VERSION "K24_CVT"

NS_ :

BS_:

BU_: METER PCM UNKNOWN VSA

BO_ 316 PCM_0x13C: 8 PCM
 SG_ TORQUE_ESTIMATE : 7|16@0- (1,0) [-32768|32767] "raw"  UNKNOWN
 SG_ TORQUE_TARGET : 23|16@0- (1,0) [-32768|32767] "raw"  UNKNOWN
 SG_ APP_SENSOR : 32|8@1+ (0.39215686274509803,0) [0|100] "%"  UNKNOWN
 SG_ TORQUE_STATE : 40|2@1+ (1,0) [0|3] ""  UNKNOWN
 SG_ RSVD_1 : 42|2@1+ (1,0) [0|3] ""  UNKNOWN
 SG_ RSVD_2 : 44|1@1+ (1,0) [0|1] ""  UNKNOWN
 SG_ FRAME_1AA_WINDOW_LATCH : 45|1@1+ (1,0) [0|1] ""  UNKNOWN
 SG_ START_PHASE_LATCH : 46|1@1+ (1,0) [0|1] ""  UNKNOWN
 SG_ DTC_STATUS_7_LATCH : 47|1@1+ (1,0) [0|1] ""  UNKNOWN
 SG_ STOP_CONTACT_GUARD_RAW : 48|1@1+ (1,0) [0|1] ""  UNKNOWN
 SG_ RSVD_3 : 49|1@1+ (1,0) [0|1] ""  UNKNOWN
 SG_ CLUTCH_PEDAL_POSITION_SWITCH_B_STATUS : 50|1@1+ (1,0) [0|1] ""  UNKNOWN
 SG_ RSVD_4 : 51|5@1+ (1,0) [0|31] ""  UNKNOWN
 SG_ CHECKSUM : 56|4@1+ (1,0) [0|15] ""  UNKNOWN
 SG_ COUNTER : 60|2@1+ (1,0) [0|3] ""  UNKNOWN
 SG_ INITIALIZED_STATUS_RAW : 62|1@1+ (1,0) [0|1] ""  UNKNOWN
 SG_ FRAME_1AA_INVALID_OR_FALLBACK_STATE_TBD : 63|1@1+ (1,0) [0|1] ""  UNKNOWN
VAL_ 316 CLUTCH_PEDAL_POSITION_SWITCH_B_STATUS 0 "OPEN" 1 "CLOSE" ;
VAL_ 316 TORQUE_STATE 0 "NORMAL" 1 "VSA_CONTROL_CANDIDATE" 2 "FUEL_CUT" 3 "UNKNOWN" ;

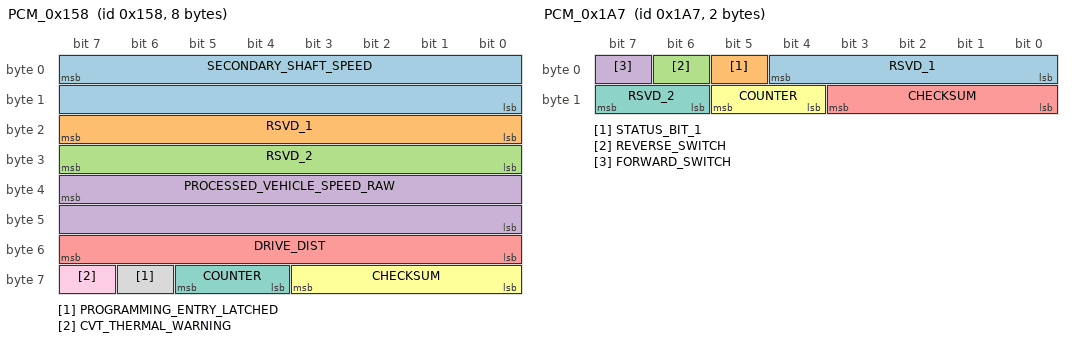
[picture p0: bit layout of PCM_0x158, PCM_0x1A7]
BO_ 344 PCM_0x158: 8 PCM
 SG_ SECONDARY_SHAFT_SPEED : 7|16@0+ (0.01,0) [0|655.35] "km/h"  UNKNOWN
 SG_ RSVD_1 : 16|8@1+ (1,0) [0|255] ""  UNKNOWN
 SG_ RSVD_2 : 24|8@1+ (1,0) [0|255] ""  UNKNOWN
 SG_ PROCESSED_VEHICLE_SPEED_RAW : 39|16@0+ (0.01,0) [0|655.35] "km/h"  UNKNOWN
 SG_ DRIVE_DIST : 48|8@1+ (10,0) [0|2550] "m"  UNKNOWN
 SG_ CHECKSUM : 56|4@1+ (1,0) [0|15] ""  UNKNOWN
 SG_ COUNTER : 60|2@1+ (1,0) [0|3] ""  UNKNOWN
 SG_ PROGRAMMING_ENTRY_LATCHED : 62|1@1+ (1,0) [0|1] ""  UNKNOWN
 SG_ CVT_THERMAL_WARNING : 63|1@1+ (1,0) [0|1] ""  UNKNOWN

BO_ 380 PCM_0x17C: 8 PCM
 SG_ APP_SENSOR : 0|8@1+ (0.39215686274509803,0) [0|100] "%"  UNKNOWN
 SG_ THROTTLE_ABOVE_IDLE_CODE : 8|8@1+ (0.4,0) [0|102] "deg"  UNKNOWN
 SG_ ENGINE_SPEED : 23|16@0+ (1,0) [0|65535] "rpm"  UNKNOWN
 SG_ BRAKE_SWITCH : 32|1@1+ (1,0) [0|1] ""  UNKNOWN
 SG_ CRUISE_CANCEL_EVENT : 33|1@1+ (1,0) [0|1] ""  UNKNOWN
 SG_ CRUISE_FAULT_SPEED_INHIBIT : 34|1@1+ (1,0) [0|1] ""  UNKNOWN
 SG_ CRUISE_ENGAGED : 35|1@1+ (1,0) [0|1] ""  UNKNOWN
 SG_ MIL : 36|1@1+ (1,0) [0|1] ""  UNKNOWN
 SG_ MIL_STATUS : 37|1@1+ (1,0) [0|1] ""  UNKNOWN
 SG_ CRUISE_INDICATOR : 38|1@1+ (1,0) [0|1] ""  UNKNOWN
 SG_ GAS_PEDAL_PRESSED : 39|1@1+ (1,0) [0|1] ""  UNKNOWN
 SG_ RSVD_1 : 40|1@1+ (1,0) [0|1] ""  UNKNOWN
 SG_ APPLICATION_STATUS_ASSERTED : 41|1@1+ (1,0) [0|1] ""  UNKNOWN
 SG_ ACCEL_PEDAL_FAULT : 42|1@1+ (1,0) [0|1] ""  UNKNOWN
 SG_ RSVD_2 : 43|2@1+ (1,0) [0|3] ""  UNKNOWN
 SG_ IDLE_STOP_PRIMARY_CONTROL : 45|1@1+ (1,0) [0|1] ""  UNKNOWN
 SG_ DC_DC_CONVERTER_INFORMATION_CST_OUTPUT : 46|1@1+ (1,0) [0|1] ""  UNKNOWN
 SG_ ENGINE_IDLE_STOP_MODE_CONTROL : 47|1@1+ (1,0) [0|1] ""  UNKNOWN
 SG_ RSVD_3 : 48|5@1+ (1,0) [0|31] ""  UNKNOWN
 SG_ CRUISE_BRAKE_SW_IDLE_STOP_SW : 53|1@1+ (1,0) [0|1] ""  UNKNOWN
 SG_ CRUISE_TRANS_REQUEST_WIRE : 54|2@1+ (1,0) [0|3] ""  UNKNOWN
 SG_ CHECKSUM : 56|4@1+ (1,0) [0|15] ""  UNKNOWN
 SG_ COUNTER : 60|2@1+ (1,0) [0|3] ""  UNKNOWN
 SG_ RSVD_4 : 62|1@1+ (1,0) [0|1] ""  UNKNOWN
 SG_ FIWARN : 63|1@1+ (1,0) [0|1] ""  UNKNOWN
VAL_ 380 CRUISE_BRAKE_SW_IDLE_STOP_SW 0 "CLOSE" 1 "OPEN" ;
VAL_ 380 ENGINE_IDLE_STOP_MODE_CONTROL 0 "UNCONTROLLED" 1 "CONTROLLED" ;
VAL_ 380 CRUISE_INDICATOR 0 "OFF" 1 "ON" ;
VAL_ 380 MIL_STATUS 0 "OFF" 1 "ON" ;
VAL_ 380 MIL 0 "OFF" 1 "ON" ;
VAL_ 380 BRAKE_SWITCH 0 "OFF" 1 "ON" ;

BO_ 401 PCM_0x191: 8 PCM
 SG_ A_T_P_SWITCH : 0|1@1+ (1,0) [0|1] ""  METER,VSA
 SG_ A_T_R_SWITCH : 1|1@1+ (1,0) [0|1] ""  METER,VSA
 SG_ A_T_N_SWITCH : 2|1@1+ (1,0) [0|1] ""  METER,VSA
 SG_ A_T_D_SWITCH : 3|1@1+ (1,0) [0|1] ""  METER,VSA
 SG_ A_T_S_SWITCH : 4|1@1+ (1,0) [0|1] ""  METER,VSA
 SG_ A_T_L_SWITCH : 5|1@1+ (1,0) [0|1] ""  METER,VSA
 SG_ RSVD_1 : 6|1@1+ (1,0) [0|1] ""  METER,VSA
 SG_ TRANSMISSION_FAULT : 7|1@1+ (1,0) [0|1] ""  METER,VSA
 SG_ RSVD_2 : 8|4@1+ (1,0) [0|15] ""  METER,VSA
 SG_ LED_C : 12|1@1+ (1,0) [0|1] ""  METER,VSA
 SG_ LED_B : 13|1@1+ (1,0) [0|1] ""  METER,VSA
 SG_ LED_A : 14|1@1+ (1,0) [0|1] ""  METER,VSA
 SG_ RSVD_3 : 15|1@1+ (1,0) [0|1] ""  METER,VSA
 SG_ RSVD_4 : 16|1@1+ (1,0) [0|1] ""  METER,VSA
 SG_ ECON_MODE_INDICATOR : 17|1@1+ (1,0) [0|1] ""  METER,VSA
 SG_ RSVD_5 : 18|1@1+ (1,0) [0|1] ""  METER,VSA
 SG_ MANUAL_MODE_INDICATOR : 19|1@1+ (1,0) [0|1] ""  METER,VSA
 SG_ CVT_CRITICAL_FAULT : 20|1@1+ (1,0) [0|1] ""  METER,VSA
 SG_ RSVD_6 : 21|1@1+ (1,0) [0|1] ""  METER,VSA
 SG_ COMMUNICATION_SPEED_FAULT : 22|1@1+ (1,0) [0|1] ""  METER,VSA
 SG_ RANGE_DISPLAY_CONTROL : 23|1@1+ (1,0) [0|1] ""  METER,VSA
 SG_ PULLEY_RATIO : 24|8@1+ (0.015625,0) [0|3.984375] "ratio"  METER,VSA
 SG_ CVT_RATIO_TARGET : 32|8@1+ (0.015625,0) [0|3.984375] "ratio"  METER,VSA
 SG_ RANGE_DISPLAY : 40|4@1+ (1,0) [0|15] ""  METER,VSA
 SG_ RSVD_7 : 44|2@1+ (1,0) [0|3] ""  METER,VSA
 SG_ CVT_FLUID_SERVICE_RESET : 46|1@1+ (1,0) [0|1] ""  METER,VSA
 SG_ CVT_FLUID_SERVICE_DUE : 47|1@1+ (1,0) [0|1] ""  METER,VSA
 SG_ CVT_CONTROL_SCHEDULE_CODE : 48|8@1+ (1,0) [0|255] ""  METER,VSA
 SG_ CHECKSUM : 56|4@1+ (1,0) [0|15] ""  METER,VSA
 SG_ COUNTER : 60|2@1+ (1,0) [0|3] ""  METER,VSA
 SG_ CVT_RATIO_RANGE_QUALIFIED : 62|1@1+ (1,0) [0|1] ""  METER,VSA
 SG_ CVT_AUTO_STOP_HOLD : 63|1@1+ (1,0) [0|1] ""  METER,VSA
VAL_ 401 CVT_CONTROL_SCHEDULE_CODE 17 "MANUAL_16_GEAR_STEP_1_7" 18 "MANUAL_16_GEAR_STEP_1_7" 19 "MANUAL_16_GEAR_STEP_1_7" 20 "MANUAL_16_GEAR_STEP_1_7" 21 "MANUAL_16_GEAR_STEP_1_7" 22 "MANUAL_16_GEAR_STEP_1_7" 23 "MANUAL_16_GEAR_STEP_1_7" 33 "ALT_MANUAL_32_GEAR_STEP_1_7" 34 "ALT_MANUAL_32_GEAR_STEP_1_7" 35 "ALT_MANUAL_32_GEAR_STEP_1_7" 36 "ALT_MANUAL_32_GEAR_STEP_1_7" 37 "ALT_MANUAL_32_GEAR_STEP_1_7" 38 "ALT_MANUAL_32_GEAR_STEP_1_7" 39 "ALT_MANUAL_32_GEAR_STEP_1_7" 81 "OVERRIDE_BRANCH" 90 "OVERRIDE_BRANCH" 127 "FAULT_LATCH_OVERRIDE" ;
VAL_ 401 RANGE_DISPLAY 0 "BLANK" 1 "P" 2 "R" 3 "N" 4 "D" 6 "UNRESOLVED" 7 "L" 8 "UNRESOLVED" 10 "S_0X0A" 15 "ALL_SEGMENTS" ;
VAL_ 401 MANUAL_MODE_INDICATOR 0 "OFF" 1 "ON" ;
VAL_ 401 ECON_MODE_INDICATOR 0 "OFF" 1 "ON" ;
VAL_ 401 LED_A 0 "OFF" 1 "ON" ;
VAL_ 401 LED_B 0 "OFF" 1 "ON" ;
VAL_ 401 LED_C 0 "OFF" 1 "ON" ;
VAL_ 401 A_T_L_SWITCH 0 "OFF" 1 "ON" ;
VAL_ 401 A_T_S_SWITCH 0 "OFF" 1 "ON" ;
VAL_ 401 A_T_D_SWITCH 0 "OFF" 1 "ON" ;
VAL_ 401 A_T_N_SWITCH 0 "OFF" 1 "ON" ;
VAL_ 401 A_T_R_SWITCH 0 "OFF" 1 "ON" ;
VAL_ 401 A_T_P_SWITCH 0 "OFF" 1 "ON" ;

BO_ 423 PCM_0x1A7: 2 PCM
 SG_ RSVD_1 : 0|5@1+ (1,0) [0|31] ""  UNKNOWN
 SG_ STATUS_BIT_1 : 5|1@1+ (1,0) [0|1] ""  UNKNOWN
 SG_ REVERSE_SWITCH : 6|1@1+ (1,0) [0|1] ""  UNKNOWN
 SG_ FORWARD_SWITCH : 7|1@1+ (1,0) [0|1] ""  UNKNOWN
 SG_ CHECKSUM : 8|4@1+ (1,0) [0|15] ""  UNKNOWN
 SG_ COUNTER : 12|2@1+ (1,0) [0|3] ""  UNKNOWN
 SG_ RSVD_2 : 14|2@1+ (1,0) [0|3] ""  UNKNOWN

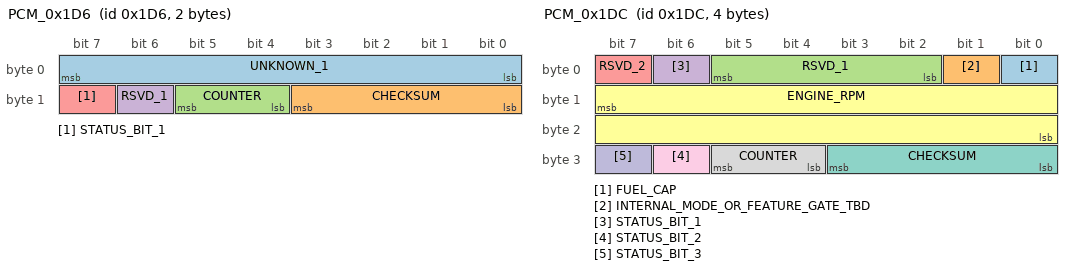
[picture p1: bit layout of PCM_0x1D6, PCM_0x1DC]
BO_ 470 PCM_0x1D6: 2 PCM
 SG_ UNKNOWN_1 : 0|8@1+ (1,0) [0|255] ""  UNKNOWN
 SG_ CHECKSUM : 8|4@1+ (1,0) [0|15] ""  UNKNOWN
 SG_ COUNTER : 12|2@1+ (1,0) [0|3] ""  UNKNOWN
 SG_ RSVD_1 : 14|1@1+ (1,0) [0|1] ""  UNKNOWN
 SG_ STATUS_BIT_1 : 15|1@1+ (1,0) [0|1] ""  UNKNOWN

BO_ 476 PCM_0x1DC: 4 PCM
 SG_ FUEL_CAP : 0|1@1+ (1,0) [0|1] ""  UNKNOWN
 SG_ INTERNAL_MODE_OR_FEATURE_GATE_TBD : 1|1@1+ (1,0) [0|1] ""  UNKNOWN
 SG_ RSVD_1 : 2|4@1+ (1,0) [0|15] ""  UNKNOWN
 SG_ STATUS_BIT_1 : 6|1@1+ (1,0) [0|1] ""  UNKNOWN
 SG_ RSVD_2 : 7|1@1+ (1,0) [0|1] ""  UNKNOWN
 SG_ ENGINE_RPM : 15|16@0+ (1,0) [0|65535] "rpm"  UNKNOWN
 SG_ CHECKSUM : 24|4@1+ (1,0) [0|15] ""  UNKNOWN
 SG_ COUNTER : 28|2@1+ (1,0) [0|3] ""  UNKNOWN
 SG_ STATUS_BIT_2 : 30|1@1+ (1,0) [0|1] ""  UNKNOWN
 SG_ STATUS_BIT_3 : 31|1@1+ (1,0) [0|1] ""  UNKNOWN
VAL_ 476 FUEL_CAP 0 "CLOSE" 1 "OPEN" ;

BO_ 800 BCM_0x320: 8 PCM
 SG_ RSVD_1 : 0|6@1+ (1,0) [0|63] ""  UNKNOWN
 SG_ ENGINE_STATE_CODE_TBD : 6|2@1+ (1,0) [0|3] ""  UNKNOWN
 SG_ STATUS_BIT_1 : 8|1@1+ (1,0) [0|1] ""  UNKNOWN
 SG_ STATUS_BIT_2 : 9|1@1+ (1,0) [0|1] ""  UNKNOWN
 SG_ RSVD_2 : 10|4@1+ (1,0) [0|15] ""  UNKNOWN
 SG_ I_VTEC_INDICATOR_COMMAND : 14|1@1+ (1,0) [0|1] ""  UNKNOWN
 SG_ RSVD_3 : 15|1@1+ (1,0) [0|1] ""  UNKNOWN
 SG_ UNKNOWN_1 : 16|3@1+ (1,0) [0|7] ""  UNKNOWN
 SG_ SIGNED_CAP_OUT_OF_DOMAIN_HIGH_BITS_B2_TBD : 19|3@1+ (1,0) [0|7] ""  UNKNOWN
 SG_ STATUS_BIT_3 : 22|1@1+ (1,0) [0|1] ""  UNKNOWN
 SG_ SIGNED_CAP_OUT_OF_DOMAIN_SIGN_BIT_B2_TBD : 23|1@1+ (1,0) [0|1] ""  UNKNOWN
 SG_ RSVD_4 : 24|8@1+ (1,0) [0|255] ""  UNKNOWN
 SG_ RSVD_5 : 32|7@1+ (1,0) [0|127] ""  UNKNOWN
 SG_ STATUS_BIT_4 : 39|1@1+ (1,0) [0|1] ""  UNKNOWN
 SG_ UNKNOWN_2 : 40|3@1+ (1,0) [0|7] ""  UNKNOWN
 SG_ UNKNOWN_3 : 43|3@1+ (1,0) [0|7] ""  UNKNOWN
 SG_ SIGNED_CAP_OUT_OF_DOMAIN_HIGH_BITS_B5_TBD : 46|2@1+ (1,0) [0|3] ""  UNKNOWN
 SG_ STATUS_BIT_5 : 48|1@1+ (1,0) [0|1] ""  UNKNOWN
 SG_ RSVD_6 : 49|2@1+ (1,0) [0|3] ""  UNKNOWN
 SG_ STATUS_BIT_6 : 51|1@1+ (1,0) [0|1] ""  UNKNOWN
 SG_ RSVD_7 : 52|4@1+ (1,0) [0|15] ""  UNKNOWN
 SG_ CHECKSUM : 56|4@1+ (1,0) [0|15] ""  UNKNOWN
 SG_ COUNTER : 60|2@1+ (1,0) [0|3] ""  UNKNOWN
 SG_ STATUS_BIT_7 : 62|1@1+ (1,0) [0|1] ""  UNKNOWN
 SG_ STATUS_BIT_8 : 63|1@1+ (1,0) [0|1] ""  UNKNOWN
VAL_ 800 I_VTEC_INDICATOR_COMMAND 0 "OFF" 1 "ON" ;

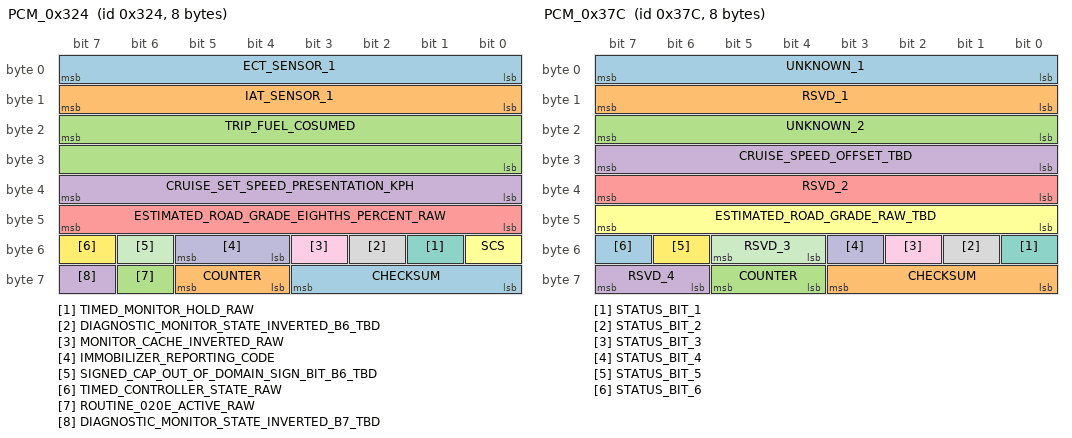
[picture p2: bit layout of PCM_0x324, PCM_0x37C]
BO_ 804 PCM_0x324: 8 PCM
 SG_ ECT_SENSOR_1 : 0|8@1+ (1,-40) [-40|215] "degC"  UNKNOWN
 SG_ IAT_SENSOR_1 : 8|8@1+ (1,-40) [-40|215] "degC"  UNKNOWN
 SG_ TRIP_FUEL_COSUMED : 23|16@0+ (1,0) [0|65535] ""  UNKNOWN
 SG_ CRUISE_SET_SPEED_PRESENTATION_KPH : 32|8@1+ (1,0) [0|255] "km/h"  UNKNOWN
 SG_ ESTIMATED_ROAD_GRADE_EIGHTHS_PERCENT_RAW : 40|8@1- (0.125,0) [-16|15.875] "%"  UNKNOWN
 SG_ SCS : 48|1@1+ (1,0) [0|1] ""  UNKNOWN
 SG_ TIMED_MONITOR_HOLD_RAW : 49|1@1+ (1,0) [0|1] ""  UNKNOWN
 SG_ DIAGNOSTIC_MONITOR_STATE_INVERTED_B6_TBD : 50|1@1+ (1,0) [0|1] ""  UNKNOWN
 SG_ MONITOR_CACHE_INVERTED_RAW : 51|1@1+ (1,0) [0|1] ""  UNKNOWN
 SG_ IMMOBILIZER_REPORTING_CODE : 52|2@1+ (1,0) [0|3] ""  UNKNOWN
 SG_ SIGNED_CAP_OUT_OF_DOMAIN_SIGN_BIT_B6_TBD : 54|1@1+ (1,0) [0|1] ""  UNKNOWN
 SG_ TIMED_CONTROLLER_STATE_RAW : 55|1@1+ (1,0) [0|1] ""  UNKNOWN
 SG_ CHECKSUM : 56|4@1+ (1,0) [0|15] ""  UNKNOWN
 SG_ COUNTER : 60|2@1+ (1,0) [0|3] ""  UNKNOWN
 SG_ ROUTINE_020E_ACTIVE_RAW : 62|1@1+ (1,0) [0|1] ""  UNKNOWN
 SG_ DIAGNOSTIC_MONITOR_STATE_INVERTED_B7_TBD : 63|1@1+ (1,0) [0|1] ""  UNKNOWN
VAL_ 804 IMMOBILIZER_REPORTING_CODE 0 "COMPLETE_ACCEPTED" 1 "INCOMPLETE" 2 "COMPLETE_NOT_ACCEPTED" ;
VAL_ 804 SCS 0 "OPEN" 1 "SHORT" ;
VAL_ 804 IAT_SENSOR_1 255 "INVALID" ;
VAL_ 804 ECT_SENSOR_1 255 "INVALID" ;

BO_ 808 XXX_0x328: 8 PCM
 SG_ RSVD_1 : 0|8@1+ (1,0) [0|255] ""  UNKNOWN
 SG_ IDLE_STOP_CVT_PREREQUISITE_RAW : 8|8@1+ (1,0) [0|255] ""  UNKNOWN
 SG_ RSVD_2 : 16|8@1+ (1,0) [0|255] ""  UNKNOWN
 SG_ RSVD_3 : 24|2@1+ (1,0) [0|3] ""  UNKNOWN
 SG_ STOCK_DISABLED_IDLE_STOP_PREREQUISITE_RAW : 26|1@1+ (1,0) [0|1] ""  UNKNOWN
 SG_ RSVD_4 : 27|5@1+ (1,0) [0|31] ""  UNKNOWN
 SG_ RSVD_5 : 32|8@1+ (1,0) [0|255] ""  UNKNOWN
 SG_ RSVD_6 : 40|2@1+ (1,0) [0|3] ""  UNKNOWN
 SG_ THROTTLE_ACTUATOR_SUPPLY_VOLTAGE_OFF_EVENT_TBD : 42|1@1+ (1,0) [0|1] ""  UNKNOWN
 SG_ STATUS_BIT_1 : 43|1@1+ (1,0) [0|1] ""  UNKNOWN
 SG_ SECONDARY_REQUEST_LIMIT_ENABLE_RAW : 44|1@1+ (1,0) [0|1] ""  UNKNOWN
 SG_ RSVD_7 : 45|1@1+ (1,0) [0|1] ""  UNKNOWN
 SG_ DISCRETE_INPUT_QUALIFICATION_RAW : 46|1@1+ (1,0) [0|1] ""  UNKNOWN
 SG_ STARTUP_QUALIFICATION_COMPLETE_RAW : 47|1@1+ (1,0) [0|1] ""  UNKNOWN
 SG_ CRUISE_TRANSITION_REASON_CODE_RAW : 48|4@1+ (1,0) [0|15] ""  UNKNOWN
 SG_ RSVD_8 : 52|2@1+ (1,0) [0|3] ""  UNKNOWN
 SG_ STATUS_BIT_2 : 54|1@1+ (1,0) [0|1] ""  UNKNOWN
 SG_ RSVD_9 : 55|1@1+ (1,0) [0|1] ""  UNKNOWN
 SG_ CHECKSUM : 56|4@1+ (1,0) [0|15] ""  UNKNOWN
 SG_ COUNTER : 60|2@1+ (1,0) [0|3] ""  UNKNOWN
 SG_ THREE_BYTE_BITWISE_INTERSECTION_NONZERO_TBD : 62|1@1+ (1,0) [0|1] ""  UNKNOWN
 SG_ ACCELERATOR_PEDAL_DUAL_TRACK_FAULT_ANY : 63|1@1+ (1,0) [0|1] ""  UNKNOWN

BO_ 892 PCM_0x37C: 8 PCM
 SG_ UNKNOWN_1 : 0|8@1+ (1,0) [0|255] ""  UNKNOWN
 SG_ RSVD_1 : 8|8@1+ (1,0) [0|255] ""  UNKNOWN
 SG_ UNKNOWN_2 : 16|8@1+ (1,0) [0|255] ""  UNKNOWN
 SG_ CRUISE_SPEED_OFFSET_TBD : 24|8@1- (0.1,0) [-12.8|12.700000000000001] "km/h"  UNKNOWN
 SG_ RSVD_2 : 32|8@1+ (1,0) [0|255] ""  UNKNOWN
 SG_ ESTIMATED_ROAD_GRADE_RAW_TBD : 40|8@1+ (1,0) [0|255] ""  UNKNOWN
 SG_ STATUS_BIT_1 : 48|1@1+ (1,0) [0|1] ""  UNKNOWN
 SG_ STATUS_BIT_2 : 49|1@1+ (1,0) [0|1] ""  UNKNOWN
 SG_ STATUS_BIT_3 : 50|1@1+ (1,0) [0|1] ""  UNKNOWN
 SG_ STATUS_BIT_4 : 51|1@1+ (1,0) [0|1] ""  UNKNOWN
 SG_ RSVD_3 : 52|2@1+ (1,0) [0|3] ""  UNKNOWN
 SG_ STATUS_BIT_5 : 54|1@1+ (1,0) [0|1] ""  UNKNOWN
 SG_ STATUS_BIT_6 : 55|1@1+ (1,0) [0|1] ""  UNKNOWN
 SG_ CHECKSUM : 56|4@1+ (1,0) [0|15] ""  UNKNOWN
 SG_ COUNTER : 60|2@1+ (1,0) [0|3] ""  UNKNOWN
 SG_ RSVD_4 : 62|2@1+ (1,0) [0|3] ""  UNKNOWN

BO_ 983 PCM_0x3D7: 8 PCM
 SG_ MULTIPLEX_HEADER : 0|8@1+ (1,0) [0|255] ""  UNKNOWN
 SG_ RETAINED_BANK_A_CODE_WORD_0_PAGE_0 m0 : 15|16@0+ (1,0) [0|65535] ""  UNKNOWN
 SG_ RETAINED_BANK_A_CODE_WORD_0_PAGE_1 m1 : 15|16@0+ (1,0) [0|65535] ""  UNKNOWN
 SG_ RETAINED_BANK_A_CODE_WORD_1_PAGE_0 m0 : 31|16@0+ (1,0) [0|65535] ""  UNKNOWN
 SG_ RETAINED_BANK_A_CODE_WORD_1_PAGE_1 m1 : 31|16@0+ (1,0) [0|65535] ""  UNKNOWN
 SG_ RETAINED_BANK_A_CODE_WORD_2_PAGE_0 m0 : 47|16@0+ (1,0) [0|65535] ""  UNKNOWN
 SG_ RETAINED_BANK_A_CODE_WORD_2_PAGE_1 m1 : 47|16@0+ (1,0) [0|65535] ""  UNKNOWN
 SG_ CHECKSUM : 56|4@1+ (1,0) [0|15] ""  UNKNOWN
 SG_ COUNTER : 60|2@1+ (1,0) [0|3] ""  UNKNOWN
 SG_ PAGE_INDEX M : 62|1@1+ (1,0) [0|1] ""  UNKNOWN
 SG_ PROTOCOL_BIT7 : 63|1@1+ (1,0) [0|1] ""  UNKNOWN
VAL_ 983 PAGE_INDEX 0 "SLOTS0_TO2" 1 "SLOTS3_TO5" ;
SG_MUL_VAL_ 983 RETAINED_BANK_A_CODE_WORD_0_PAGE_0 PAGE_INDEX 0-0;
SG_MUL_VAL_ 983 RETAINED_BANK_A_CODE_WORD_0_PAGE_1 PAGE_INDEX 1-1;
SG_MUL_VAL_ 983 RETAINED_BANK_A_CODE_WORD_1_PAGE_0 PAGE_INDEX 0-0;
SG_MUL_VAL_ 983 RETAINED_BANK_A_CODE_WORD_1_PAGE_1 PAGE_INDEX 1-1;
SG_MUL_VAL_ 983 RETAINED_BANK_A_CODE_WORD_2_PAGE_0 PAGE_INDEX 0-0;
SG_MUL_VAL_ 983 RETAINED_BANK_A_CODE_WORD_2_PAGE_1 PAGE_INDEX 1-1;

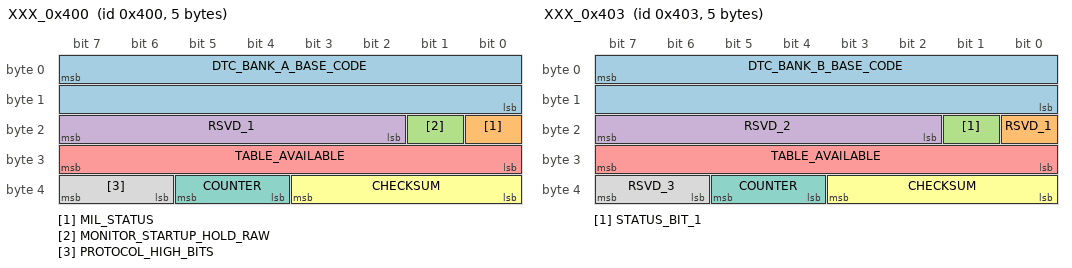
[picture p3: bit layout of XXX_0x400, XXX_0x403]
BO_ 1024 XXX_0x400: 5 PCM
 SG_ DTC_BANK_A_BASE_CODE : 7|16@0+ (1,0) [0|65535] ""  UNKNOWN
 SG_ MIL_STATUS : 16|1@1+ (1,0) [0|1] ""  UNKNOWN
 SG_ MONITOR_STARTUP_HOLD_RAW : 17|1@1+ (1,0) [0|1] ""  UNKNOWN
 SG_ RSVD_1 : 18|6@1+ (1,0) [0|63] ""  UNKNOWN
 SG_ TABLE_AVAILABLE : 24|8@1+ (1,0) [0|255] ""  UNKNOWN
 SG_ CHECKSUM : 32|4@1+ (1,0) [0|15] ""  UNKNOWN
 SG_ COUNTER : 36|2@1+ (1,0) [0|3] ""  UNKNOWN
 SG_ PROTOCOL_HIGH_BITS : 38|2@1+ (1,0) [0|3] ""  UNKNOWN
VAL_ 1024 MIL_STATUS 0 "OFF" 1 "ON" ;

BO_ 1027 XXX_0x403: 5 PCM
 SG_ DTC_BANK_B_BASE_CODE : 7|16@0+ (1,0) [0|65535] ""  UNKNOWN
 SG_ RSVD_1 : 16|1@1+ (1,0) [0|1] ""  UNKNOWN
 SG_ STATUS_BIT_1 : 17|1@1+ (1,0) [0|1] ""  UNKNOWN
 SG_ RSVD_2 : 18|6@1+ (1,0) [0|63] ""  UNKNOWN
 SG_ TABLE_AVAILABLE : 24|8@1+ (1,0) [0|255] ""  UNKNOWN
 SG_ CHECKSUM : 32|4@1+ (1,0) [0|15] ""  UNKNOWN
 SG_ COUNTER : 36|2@1+ (1,0) [0|3] ""  UNKNOWN
 SG_ RSVD_3 : 38|2@1+ (1,0) [0|3] ""  UNKNOWN

BO_ 1036 XXX_0x40C: 8 PCM
 SG_ MULTIPLEX_PAGE M : 0|4@1+ (1,0) [0|15] ""  UNKNOWN
 SG_ MULTIPLEX_GROUP : 4|2@1+ (1,0) [0|3] ""  UNKNOWN
 SG_ DIAGNOSTIC_EVENT_STATE : 6|2@1+ (1,0) [0|3] ""  UNKNOWN
 SG_ RSVD_1 m0 : 8|8@1+ (1,0) [0|255] ""  UNKNOWN
 SG_ P01_VIN_CHARACTERS_1_6_10_B1 m1 : 8|8@1+ (1,0) [0|255] ""  UNKNOWN
 SG_ P02_VIN_CHARACTERS_7_12_11_B1 m2 : 8|8@1+ (1,0) [0|255] ""  UNKNOWN
 SG_ P03_VIN_CHARACTERS_13_17_12_B1 m3 : 8|8@1+ (1,0) [0|255] ""  UNKNOWN
 SG_ P04_ECUID1 m4 : 8|8@1+ (1,0) [0|255] ""  UNKNOWN
 SG_ P05_ENGINE_SPEED m5 : 15|16@0+ (0.25,0) [0|16383.75] "rpm"  UNKNOWN
 SG_ P06_IAT_SENSOR_1_V m6 : 8|8@1+ (0.0196078431372549,0) [0|5] "V"  UNKNOWN
 SG_ P07_VEHICLE_SPEED_PCM m7 : 8|8@1+ (1,0) [0|255] "km/h"  UNKNOWN
 SG_ P08_APP_SENSOR m8 : 15|16@0+ (0.005,0) [0|327.675] "%"  UNKNOWN
 SG_ P09_TARGET_TH_VLV m9 : 15|16@0+ (0.005,0) [0|327.675] "deg"  UNKNOWN
 SG_ RSVD_2 m10 : 8|8@1+ (1,0) [0|255] ""  UNKNOWN
 SG_ P0B_FSS m11 : 8|8@1+ (1,0) [0|255] ""  UNKNOWN
 SG_ RSVD_3 m12 : 8|8@1+ (1,0) [0|255] ""  UNKNOWN
 SG_ RSVD_4 m13 : 8|8@1+ (1,0) [0|255] ""  UNKNOWN
 SG_ P0E_MAF_SENSOR m14 : 15|16@0+ (0.01,0) [0|655.35] "g/s"  UNKNOWN
 SG_ P0F_FUEL_LEVEL m15 : 8|8@1+ (0.39215686274509803,0) [0|100] "%"  UNKNOWN
 SG_ P00_DIAGNOSTICEVENTORFREEZEDTCCODE_5 m0 : 23|16@0+ (1,0) [0|65535] ""  UNKNOWN
 SG_ P01_VIN_CHARACTERS_1_6_10_B2 m1 : 16|8@1+ (1,0) [0|255] ""  UNKNOWN
 SG_ P02_VIN_CHARACTERS_7_12_11_B2 m2 : 16|8@1+ (1,0) [0|255] ""  UNKNOWN
 SG_ P03_VIN_CHARACTERS_13_17_12_B2 m3 : 16|8@1+ (1,0) [0|255] ""  UNKNOWN
 SG_ P04_ECUID2 m4 : 16|8@1+ (1,0) [0|255] ""  UNKNOWN
 SG_ P06_IAT_SENSOR_1_DEG_C m6 : 16|8@1+ (1,-40) [-40|215] "degC"  UNKNOWN
 SG_ P07_CLV m7 : 16|8@1+ (0.39215686274509803,0) [0|100] "%"  UNKNOWN
 SG_ RSVD_5 m10 : 16|8@1+ (1,0) [0|255] ""  UNKNOWN
 SG_ P0B_HO2S_S2 m11 : 16|8@1+ (0.0196078431372549,0) [0|5] "V"  UNKNOWN
 SG_ RSVD_6 m12 : 16|8@1+ (1,0) [0|255] ""  UNKNOWN
 SG_ P0D_AF_SENSOR m13 : 23|16@0+ (1,0) [0|65535] ""  UNKNOWN
 SG_ RSVD_7 m15 : 16|8@1+ (1,0) [0|255] ""  UNKNOWN
 SG_ P01_VIN_CHARACTERS_1_6_10_B3 m1 : 24|8@1+ (1,0) [0|255] ""  UNKNOWN
 SG_ P02_VIN_CHARACTERS_7_12_11_B3 m2 : 24|8@1+ (1,0) [0|255] ""  UNKNOWN
 SG_ P03_VIN_CHARACTERS_13_17_12_B3 m3 : 24|8@1+ (1,0) [0|255] ""  UNKNOWN
 SG_ P04_ECUID3 m4 : 24|8@1+ (1,0) [0|255] ""  UNKNOWN
 SG_ P05_TP_SENSOR m5 : 24|8@1+ (0.39215686274509803,0) [0|100] "%"  UNKNOWN
 SG_ P06_MAP_SENSOR_V m6 : 24|8@1+ (0.0196078431372549,0) [0|5] "V"  UNKNOWN
 SG_ P07_SPARK_ADVANCE m7 : 24|8@1+ (0.5,-64) [-64|63.5] "deg"  UNKNOWN
 SG_ P08_TP_SENSOR_1 m8 : 24|8@1+ (0.0196078431372549,0) [0|5] "V"  UNKNOWN
 SG_ P09_THROTTLE_AN12_BASELINE_RAW m9 : 24|8@1+ (1,0) [0|255] ""  UNKNOWN
 SG_ P0A_AF_LAMBDA m10 : 31|16@0+ (3.0517578125e-05,0) [0|1.999969482421875] "ratio"  UNKNOWN
 SG_ RSVD_8 m11 : 24|8@1+ (1,0) [0|255] ""  UNKNOWN
 SG_ RSVD_9 m12 : 24|8@1+ (1,0) [0|255] ""  UNKNOWN
 SG_ P0E_CMP_CTRL m14 : 24|8@1+ (1,0) [0|255] ""  UNKNOWN
 SG_ RSVD_10 m15 : 24|8@1+ (1,0) [0|255] ""  UNKNOWN
 SG_ P00_FORMATORLENGTHCODE_6 m0 : 32|8@1+ (1,0) [0|255] ""  UNKNOWN
 SG_ P01_VIN_CHARACTERS_1_6_10_B4 m1 : 32|8@1+ (1,0) [0|255] ""  UNKNOWN
 SG_ P02_VIN_CHARACTERS_7_12_11_B4 m2 : 32|8@1+ (1,0) [0|255] ""  UNKNOWN
 SG_ P03_VIN_CHARACTERS_13_17_12_B4 m3 : 32|8@1+ (1,0) [0|255] ""  UNKNOWN
 SG_ P04_ECUID4 m4 : 32|8@1+ (1,0) [0|255] ""  UNKNOWN
 SG_ P05_REL_TP_SENSOR m5 : 32|8@1+ (0.39215686274509803,0) [0|100] "%"  UNKNOWN
 SG_ P06_MAP_SENSOR_K_PA m6 : 32|8@1+ (1,0) [0|255] "kPa"  UNKNOWN
 SG_ P07_CONTROL_MODULE_VOLTAGE_CLAMPED_RAW m7 : 32|8@1+ (1,0) [0|255] "raw"  UNKNOWN
 SG_ P08_TP_SENSOR_2 m8 : 32|8@1+ (0.0196078431372549,0) [0|5] "V"  UNKNOWN
 SG_ P09_THROTTLE_AN45_BASELINE_RAW m9 : 32|8@1+ (1,0) [0|255] ""  UNKNOWN
 SG_ RSVD_11 m11 : 32|8@1+ (1,0) [0|255] ""  UNKNOWN
 SG_ RSVD_12 m12 : 32|8@1+ (1,0) [0|255] ""  UNKNOWN
 SG_ P0D_MAF_SENSOR m13 : 32|8@1+ (0.0196078431372549,0) [0|5] "V"  UNKNOWN
 SG_ P0E_ENGINE_RUNTIME_RAW m14 : 39|16@0+ (1,0) [0|65535] "s"  UNKNOWN
 SG_ RSVD_13 m15 : 32|8@1+ (1,0) [0|255] ""  UNKNOWN
 SG_ RSVD_14 m0 : 40|8@1+ (1,0) [0|255] ""  UNKNOWN
 SG_ P01_VIN_CHARACTERS_1_6_10_B5 m1 : 40|8@1+ (1,0) [0|255] ""  UNKNOWN
 SG_ P02_VIN_CHARACTERS_7_12_11_B5 m2 : 40|8@1+ (1,0) [0|255] ""  UNKNOWN
 SG_ P03_VIN_CHARACTERS_13_17_12_B5 m3 : 40|8@1+ (1,0) [0|255] ""  UNKNOWN
 SG_ P04_ECUID5 m4 : 40|8@1+ (1,0) [0|255] ""  UNKNOWN
 SG_ P05_ECT_SENSOR_1_V m5 : 40|8@1+ (0.0196078431372549,0) [0|5] "V"  UNKNOWN
 SG_ P06_BARO_SENSOR_V m6 : 40|8@1+ (0.0196078431372549,0) [0|5] "V"  UNKNOWN
 SG_ P07_APP_SENSOR_A m7 : 40|8@1+ (0.0196078431372549,0) [0|5] "V"  UNKNOWN
 SG_ P08_THROTTLE_VLV m8 : 47|16@0+ (0.005,0) [0|327.675] "deg"  UNKNOWN
 SG_ P09_IDLE_TARGET_TH m9 : 47|16@0+ (0.005,0) [0|327.675] "deg"  UNKNOWN
 SG_ P0A_AF_FB_ST_FUEL_TRIM m10 : 40|8@1+ (0.0078125,0) [0|1.9921875] "ratio"  UNKNOWN
 SG_ RSVD_15 m11 : 40|8@1+ (1,0) [0|255] ""  UNKNOWN
 SG_ P0C_F_INJECTOR m12 : 47|16@0+ (0.004,0) [0|262.14] "ms"  UNKNOWN
 SG_ P0D_AF_LAMBDA_CMD m13 : 47|16@0+ (3.0517578125e-05,0) [0|1.999969482421875] "ratio"  UNKNOWN
 SG_ RSVD_16 m15 : 40|8@1+ (1,0) [0|255] ""  UNKNOWN
 SG_ RSVD_17 m0 : 48|8@1+ (1,0) [0|255] ""  UNKNOWN
 SG_ P01_VIN_CHARACTERS_1_6_10_B6 m1 : 48|8@1+ (1,0) [0|255] ""  UNKNOWN
 SG_ P02_VIN_CHARACTERS_7_12_11_B6 m2 : 48|8@1+ (1,0) [0|255] ""  UNKNOWN
 SG_ P03_IDENTIFICATIONEXTRABYTE_TBD_13 m3 : 48|8@1+ (1,0) [0|255] ""  UNKNOWN
 SG_ RSVD_18 m4 : 48|8@1+ (1,0) [0|255] ""  UNKNOWN
 SG_ P05_ECT_SENSOR_1_DEG_C m5 : 48|8@1+ (1,-40) [-40|215] "degC"  UNKNOWN
 SG_ P06_BARO_SENSOR_K_PA m6 : 48|8@1+ (1,0) [0|255] "kPa"  UNKNOWN
 SG_ P07_APP_SENSOR_B m7 : 48|8@1+ (0.0196078431372549,0) [0|5] "V"  UNKNOWN
 SG_ P0A_AF_FB_AVE_LT_FUEL_TRIM m10 : 48|8@1+ (0.0078125,0) [0|1.9921875] "ratio"  UNKNOWN
 SG_ RSVD_19 m11 : 48|8@1+ (1,0) [0|255] ""  UNKNOWN
 SG_ P0E_EVAP_PC_DUTY m14 : 48|8@1+ (0.39215686274509803,0) [0|100] "%"  UNKNOWN
 SG_ RSVD_20 m15 : 48|8@1+ (1,0) [0|255] ""  UNKNOWN
 SG_ CHECKSUM : 56|4@1+ (1,0) [0|15] ""  UNKNOWN
 SG_ COUNTER : 60|2@1+ (1,0) [0|3] ""  UNKNOWN
 SG_ DIAGNOSTIC_STATUS_FLAG6 : 62|1@1+ (1,0) [0|1] ""  UNKNOWN
 SG_ DIAGNOSTIC_STATUS_FLAG7 : 63|1@1+ (1,0) [0|1] ""  UNKNOWN
VAL_ 1036 P0B_FSS 0 "NONE" 1 "OL_COND" 2 "CLOSED" 4 "OL_DRV" 8 "OL_DTC" 16 "CL_O2_SX" ;
SG_MUL_VAL_ 1036 RSVD_1 MULTIPLEX_PAGE 0-0;
SG_MUL_VAL_ 1036 P01_VIN_CHARACTERS_1_6_10_B1 MULTIPLEX_PAGE 1-1;
SG_MUL_VAL_ 1036 P02_VIN_CHARACTERS_7_12_11_B1 MULTIPLEX_PAGE 2-2;
SG_MUL_VAL_ 1036 P03_VIN_CHARACTERS_13_17_12_B1 MULTIPLEX_PAGE 3-3;
SG_MUL_VAL_ 1036 P04_ECUID1 MULTIPLEX_PAGE 4-4;
SG_MUL_VAL_ 1036 P05_ENGINE_SPEED MULTIPLEX_PAGE 5-5;
SG_MUL_VAL_ 1036 P06_IAT_SENSOR_1_V MULTIPLEX_PAGE 6-6;
SG_MUL_VAL_ 1036 P07_VEHICLE_SPEED_PCM MULTIPLEX_PAGE 7-7;
SG_MUL_VAL_ 1036 P08_APP_SENSOR MULTIPLEX_PAGE 8-8;
SG_MUL_VAL_ 1036 P09_TARGET_TH_VLV MULTIPLEX_PAGE 9-9;
SG_MUL_VAL_ 1036 RSVD_2 MULTIPLEX_PAGE 10-10;
SG_MUL_VAL_ 1036 P0B_FSS MULTIPLEX_PAGE 11-11;
SG_MUL_VAL_ 1036 RSVD_3 MULTIPLEX_PAGE 12-12;
SG_MUL_VAL_ 1036 RSVD_4 MULTIPLEX_PAGE 13-13;
SG_MUL_VAL_ 1036 P0E_MAF_SENSOR MULTIPLEX_PAGE 14-14;
SG_MUL_VAL_ 1036 P0F_FUEL_LEVEL MULTIPLEX_PAGE 15-15;
SG_MUL_VAL_ 1036 P00_DIAGNOSTICEVENTORFREEZEDTCCODE_5 MULTIPLEX_PAGE 0-0;
SG_MUL_VAL_ 1036 P01_VIN_CHARACTERS_1_6_10_B2 MULTIPLEX_PAGE 1-1;
SG_MUL_VAL_ 1036 P02_VIN_CHARACTERS_7_12_11_B2 MULTIPLEX_PAGE 2-2;
SG_MUL_VAL_ 1036 P03_VIN_CHARACTERS_13_17_12_B2 MULTIPLEX_PAGE 3-3;
SG_MUL_VAL_ 1036 P04_ECUID2 MULTIPLEX_PAGE 4-4;
SG_MUL_VAL_ 1036 P06_IAT_SENSOR_1_DEG_C MULTIPLEX_PAGE 6-6;
SG_MUL_VAL_ 1036 P07_CLV MULTIPLEX_PAGE 7-7;
SG_MUL_VAL_ 1036 RSVD_5 MULTIPLEX_PAGE 10-10;
SG_MUL_VAL_ 1036 P0B_HO2S_S2 MULTIPLEX_PAGE 11-11;
SG_MUL_VAL_ 1036 RSVD_6 MULTIPLEX_PAGE 12-12;
SG_MUL_VAL_ 1036 P0D_AF_SENSOR MULTIPLEX_PAGE 13-13;
SG_MUL_VAL_ 1036 RSVD_7 MULTIPLEX_PAGE 15-15;
SG_MUL_VAL_ 1036 P01_VIN_CHARACTERS_1_6_10_B3 MULTIPLEX_PAGE 1-1;
SG_MUL_VAL_ 1036 P02_VIN_CHARACTERS_7_12_11_B3 MULTIPLEX_PAGE 2-2;
SG_MUL_VAL_ 1036 P03_VIN_CHARACTERS_13_17_12_B3 MULTIPLEX_PAGE 3-3;
SG_MUL_VAL_ 1036 P04_ECUID3 MULTIPLEX_PAGE 4-4;
SG_MUL_VAL_ 1036 P05_TP_SENSOR MULTIPLEX_PAGE 5-5;
SG_MUL_VAL_ 1036 P06_MAP_SENSOR_V MULTIPLEX_PAGE 6-6;
SG_MUL_VAL_ 1036 P07_SPARK_ADVANCE MULTIPLEX_PAGE 7-7;
SG_MUL_VAL_ 1036 P08_TP_SENSOR_1 MULTIPLEX_PAGE 8-8;
SG_MUL_VAL_ 1036 P09_THROTTLE_AN12_BASELINE_RAW MULTIPLEX_PAGE 9-9;
SG_MUL_VAL_ 1036 P0A_AF_LAMBDA MULTIPLEX_PAGE 10-10;
SG_MUL_VAL_ 1036 RSVD_8 MULTIPLEX_PAGE 11-11;
SG_MUL_VAL_ 1036 RSVD_9 MULTIPLEX_PAGE 12-12;
SG_MUL_VAL_ 1036 P0E_CMP_CTRL MULTIPLEX_PAGE 14-14;
SG_MUL_VAL_ 1036 RSVD_10 MULTIPLEX_PAGE 15-15;
SG_MUL_VAL_ 1036 P00_FORMATORLENGTHCODE_6 MULTIPLEX_PAGE 0-0;
SG_MUL_VAL_ 1036 P01_VIN_CHARACTERS_1_6_10_B4 MULTIPLEX_PAGE 1-1;
SG_MUL_VAL_ 1036 P02_VIN_CHARACTERS_7_12_11_B4 MULTIPLEX_PAGE 2-2;
SG_MUL_VAL_ 1036 P03_VIN_CHARACTERS_13_17_12_B4 MULTIPLEX_PAGE 3-3;
SG_MUL_VAL_ 1036 P04_ECUID4 MULTIPLEX_PAGE 4-4;
SG_MUL_VAL_ 1036 P05_REL_TP_SENSOR MULTIPLEX_PAGE 5-5;
SG_MUL_VAL_ 1036 P06_MAP_SENSOR_K_PA MULTIPLEX_PAGE 6-6;
SG_MUL_VAL_ 1036 P07_CONTROL_MODULE_VOLTAGE_CLAMPED_RAW MULTIPLEX_PAGE 7-7;
SG_MUL_VAL_ 1036 P08_TP_SENSOR_2 MULTIPLEX_PAGE 8-8;
SG_MUL_VAL_ 1036 P09_THROTTLE_AN45_BASELINE_RAW MULTIPLEX_PAGE 9-9;
SG_MUL_VAL_ 1036 RSVD_11 MULTIPLEX_PAGE 11-11;
SG_MUL_VAL_ 1036 RSVD_12 MULTIPLEX_PAGE 12-12;
SG_MUL_VAL_ 1036 P0D_MAF_SENSOR MULTIPLEX_PAGE 13-13;
SG_MUL_VAL_ 1036 P0E_ENGINE_RUNTIME_RAW MULTIPLEX_PAGE 14-14;
SG_MUL_VAL_ 1036 RSVD_13 MULTIPLEX_PAGE 15-15;
SG_MUL_VAL_ 1036 RSVD_14 MULTIPLEX_PAGE 0-0;
SG_MUL_VAL_ 1036 P01_VIN_CHARACTERS_1_6_10_B5 MULTIPLEX_PAGE 1-1;
SG_MUL_VAL_ 1036 P02_VIN_CHARACTERS_7_12_11_B5 MULTIPLEX_PAGE 2-2;
SG_MUL_VAL_ 1036 P03_VIN_CHARACTERS_13_17_12_B5 MULTIPLEX_PAGE 3-3;
SG_MUL_VAL_ 1036 P04_ECUID5 MULTIPLEX_PAGE 4-4;
SG_MUL_VAL_ 1036 P05_ECT_SENSOR_1_V MULTIPLEX_PAGE 5-5;
SG_MUL_VAL_ 1036 P06_BARO_SENSOR_V MULTIPLEX_PAGE 6-6;
SG_MUL_VAL_ 1036 P07_APP_SENSOR_A MULTIPLEX_PAGE 7-7;
SG_MUL_VAL_ 1036 P08_THROTTLE_VLV MULTIPLEX_PAGE 8-8;
SG_MUL_VAL_ 1036 P09_IDLE_TARGET_TH MULTIPLEX_PAGE 9-9;
SG_MUL_VAL_ 1036 P0A_AF_FB_ST_FUEL_TRIM MULTIPLEX_PAGE 10-10;
SG_MUL_VAL_ 1036 RSVD_15 MULTIPLEX_PAGE 11-11;
SG_MUL_VAL_ 1036 P0C_F_INJECTOR MULTIPLEX_PAGE 12-12;
SG_MUL_VAL_ 1036 P0D_AF_LAMBDA_CMD MULTIPLEX_PAGE 13-13;
SG_MUL_VAL_ 1036 RSVD_16 MULTIPLEX_PAGE 15-15;
SG_MUL_VAL_ 1036 RSVD_17 MULTIPLEX_PAGE 0-0;
SG_MUL_VAL_ 1036 P01_VIN_CHARACTERS_1_6_10_B6 MULTIPLEX_PAGE 1-1;
SG_MUL_VAL_ 1036 P02_VIN_CHARACTERS_7_12_11_B6 MULTIPLEX_PAGE 2-2;
SG_MUL_VAL_ 1036 P03_IDENTIFICATIONEXTRABYTE_TBD_13 MULTIPLEX_PAGE 3-3;
SG_MUL_VAL_ 1036 RSVD_18 MULTIPLEX_PAGE 4-4;
SG_MUL_VAL_ 1036 P05_ECT_SENSOR_1_DEG_C MULTIPLEX_PAGE 5-5;
SG_MUL_VAL_ 1036 P06_BARO_SENSOR_K_PA MULTIPLEX_PAGE 6-6;
SG_MUL_VAL_ 1036 P07_APP_SENSOR_B MULTIPLEX_PAGE 7-7;
SG_MUL_VAL_ 1036 P0A_AF_FB_AVE_LT_FUEL_TRIM MULTIPLEX_PAGE 10-10;
SG_MUL_VAL_ 1036 RSVD_19 MULTIPLEX_PAGE 11-11;
SG_MUL_VAL_ 1036 P0E_EVAP_PC_DUTY MULTIPLEX_PAGE 14-14;
SG_MUL_VAL_ 1036 RSVD_20 MULTIPLEX_PAGE 15-15;

BO_ 1039 XXX_0x40F: 8 PCM
 SG_ MULTIPLEX_PAGE M : 0|4@1+ (1,0) [0|15] ""  UNKNOWN
 SG_ MULTIPLEX_GROUP : 4|2@1+ (1,0) [0|3] ""  UNKNOWN
 SG_ DIAGNOSTIC_EVENT_STATE : 6|2@1+ (1,0) [0|3] ""  UNKNOWN
 SG_ UNKNOWN_1 m0 : 8|8@1+ (1,0) [0|255] ""  UNKNOWN
 SG_ UNKNOWN_2 m1 : 8|8@1+ (1,0) [0|255] ""  UNKNOWN
 SG_ P02_ENGINE_SPEED m2 : 15|16@0+ (1,0) [0|65535] "rpm"  UNKNOWN
 SG_ P03_OUTPUT_SHAFT_DRIVEN_PULLEY_SPEED_RPM m3 : 15|16@0+ (1,0) [0|65535] "rpm"  UNKNOWN
 SG_ P04_INTAKE_AIR_TEMPERATURE m4 : 8|8@1+ (1,-40) [-40|215] "degC"  UNKNOWN
 SG_ P05_APP_SENSOR m5 : 8|8@1+ (0.5,0) [0|127.5] "%"  UNKNOWN
 SG_ P06_DRIVE_PULLEY_SOL_COMMAND m6 : 8|8@1+ (0.005,0) [0|1.2750000000000001] "A"  UNKNOWN
 SG_ P07_PRESSURE_CONTROL_SOL_COMMAND m7 : 8|8@1+ (0.005,0) [0|1.2750000000000001] "A"  UNKNOWN
 SG_ RSVD_1 m8 : 8|8@1+ (1,0) [0|255] ""  UNKNOWN
 SG_ P00_FRZDTC m0 : 23|16@0+ (1,0) [0|65535] ""  UNKNOWN
 SG_ UNKNOWN_3 m1 : 16|8@1+ (1,0) [0|255] ""  UNKNOWN
 SG_ P04_BARO_SENSOR_V m4 : 16|8@1+ (0.0196,0) [0|4.998] "V"  UNKNOWN
 SG_ P05_CVTF_TEMP_SENSOR_V m5 : 16|8@1+ (0.0196,0) [0|4.998] "V"  UNKNOWN
 SG_ P06_DRIVE_PULLEY_SOL_ACTUAL m6 : 16|8@1+ (0.005,0) [0|1.2750000000000001] "A"  UNKNOWN
 SG_ P07_PRESSURE_CONTROL_SOL_ACTUAL m7 : 16|8@1+ (0.005,0) [0|1.2750000000000001] "A"  UNKNOWN
 SG_ RSVD_2 m8 : 16|8@1+ (1,0) [0|255] ""  UNKNOWN
 SG_ UNKNOWN_4 m1 : 24|8@1+ (1,0) [0|255] ""  UNKNOWN
 SG_ P02_TORQUE_CONVERTER_TURBINE_SPEED m2 : 31|16@0+ (1,0) [0|65535] "rpm"  UNKNOWN
 SG_ P03_SECONDARY_SHAFT_SPEED m3 : 24|8@1+ (1,0) [0|255] "km/h"  UNKNOWN
 SG_ P04_MAP_SENSOR_V m4 : 24|8@1+ (0.0196,0) [0|4.998] "V"  UNKNOWN
 SG_ P05_DRIVEN_PULLEY_PRESSURE_SENSOR_V m5 : 24|8@1+ (0.0196,0) [0|4.998] "V"  UNKNOWN
 SG_ P06_DRIVEN_PULLEY_SOL_COMMAND m6 : 24|8@1+ (0.005,0) [0|1.2750000000000001] "A"  UNKNOWN
 SG_ RSVD_3 m7 : 24|5@1+ (1,0) [0|31] ""  UNKNOWN
 SG_ RSVD_4 m8 : 24|8@1+ (1,0) [0|255] ""  UNKNOWN
 SG_ P07_SHIFT_SOL_O_P m7 : 29|1@1+ (1,0) [0|1] ""  UNKNOWN
 SG_ P07_SHIFT_SOL_B m7 : 30|1@1+ (1,0) [0|1] ""  UNKNOWN
 SG_ P07_SHIFT_SOL_A m7 : 31|1@1+ (1,0) [0|1] ""  UNKNOWN
 SG_ UNKNOWN_5 m0 : 32|8@1+ (1,0) [0|255] ""  UNKNOWN
 SG_ UNKNOWN_6 m1 : 32|8@1+ (1,0) [0|255] ""  UNKNOWN
 SG_ P03_ABS_WHEEL_SPEED m3 : 32|8@1+ (1,0) [0|255] "km/h"  UNKNOWN
 SG_ P04_TP_SENSOR_1 m4 : 32|8@1+ (0.0196,0) [0|4.998] "V"  UNKNOWN
 SG_ P05_INCLINATION_SENSOR_OUTPUT_VOLTAGE m5 : 32|8@1+ (0.0196,0) [0|4.998] "V"  UNKNOWN
 SG_ P06_DRIVEN_PULLEY_SOL_ACTUAL m6 : 32|8@1+ (0.005,0) [0|1.2750000000000001] "A"  UNKNOWN
 SG_ RSVD_5 m7 : 32|6@1+ (1,0) [0|63] ""  UNKNOWN
 SG_ RSVD_6 m8 : 32|8@1+ (1,0) [0|255] ""  UNKNOWN
 SG_ P07_INHIBITOR_SOL m7 : 38|1@1+ (1,0) [0|1] ""  UNKNOWN
 SG_ P07_SHIFT_LOCK_SOL m7 : 39|1@1+ (1,0) [0|1] ""  UNKNOWN
 SG_ UNKNOWN_7 m0 : 47|16@0+ (1,0) [0|65535] ""  UNKNOWN
 SG_ UNKNOWN_8 m1 : 40|8@1+ (1,0) [0|255] ""  UNKNOWN
 SG_ P02_INPUT_SHAFT_DRIVE_PULLEY_SPEED_RPM m2 : 47|16@0+ (1,0) [0|65535] "rpm"  UNKNOWN
 SG_ P03_VEHICLE_SPEED m3 : 40|8@1+ (1,0) [0|255] "km/h"  UNKNOWN
 SG_ P04_ECT_SENSOR_V m4 : 40|8@1+ (0.0196,0) [0|4.998] "V"  UNKNOWN
 SG_ P05_ELECTRIC_OIL_PUMP_RPM m5 : 40|8@1+ (50,0) [0|12750] "rpm"  UNKNOWN
 SG_ P06_LCC_LINEAR_SOL_COMMAND m6 : 40|8@1+ (0.005,0) [0|1.2750000000000001] "A"  UNKNOWN
 SG_ RSVD_7 m7 : 40|2@1+ (1,0) [0|3] ""  UNKNOWN
 SG_ RSVD_8 m8 : 40|8@1+ (1,0) [0|255] ""  UNKNOWN
 SG_ P07_A_T_L_SWITCH m7 : 42|1@1+ (1,0) [0|1] ""  UNKNOWN
 SG_ P07_A_T_S_SWITCH m7 : 43|1@1+ (1,0) [0|1] ""  UNKNOWN
 SG_ P07_A_T_D_SWITCH m7 : 44|1@1+ (1,0) [0|1] ""  UNKNOWN
 SG_ P07_A_T_N_SWITCH m7 : 45|1@1+ (1,0) [0|1] ""  UNKNOWN
 SG_ P07_A_T_R_SWITCH m7 : 46|1@1+ (1,0) [0|1] ""  UNKNOWN
 SG_ P07_A_T_P_SWITCH m7 : 47|1@1+ (1,0) [0|1] ""  UNKNOWN
 SG_ UNKNOWN_9 m1 : 48|8@1+ (1,0) [0|255] ""  UNKNOWN
 SG_ P03_DIRECTION_OF_DRIVE_PULLEY_ROTATION m3 : 48|2@1+ (1,0) [0|3] ""  UNKNOWN
 SG_ P04_BATTERY_VOLTAGE m4 : 48|8@1+ (0.1,0) [0|25.5] "V"  UNKNOWN
 SG_ RSVD_9 m5 : 48|6@1+ (1,0) [0|63] ""  UNKNOWN
 SG_ P06_LCC_LINEAR_SOL_ACTUAL m6 : 48|8@1+ (0.005,0) [0|1.2750000000000001] "A"  UNKNOWN
 SG_ RSVD_10 m7 : 48|3@1+ (1,0) [0|7] ""  UNKNOWN
 SG_ RSVD_11 m8 : 48|8@1+ (1,0) [0|255] ""  UNKNOWN
 SG_ P03_NON_CREEP_CONTROL_STATUS m3 : 50|1@1+ (1,0) [0|1] ""  UNKNOWN
 SG_ P03_FUEL_CUT_DECEL m3 : 51|1@1+ (1,0) [0|1] ""  UNKNOWN
 SG_ P07_PARK_PIN_SWITCH m7 : 51|1@1+ (1,0) [0|1] ""  UNKNOWN
 SG_ P03_DIRECTION_OF_SECONDARY_SHAFT_ROTATION m3 : 52|2@1+ (1,0) [0|3] ""  UNKNOWN
 SG_ RSVD_12 m7 : 52|2@1+ (1,0) [0|3] ""  UNKNOWN
 SG_ P03_DIRECTION_OF_TURBINE_ROTATION m3 : 54|2@1+ (1,0) [0|3] ""  UNKNOWN
 SG_ P05_BRAKE_SWITCH m5 : 54|1@1+ (1,0) [0|1] ""  UNKNOWN
 SG_ P07_REVERSE_SWITCH_ATPRVS m7 : 54|1@1+ (1,0) [0|1] ""  UNKNOWN
 SG_ P05_SCS m5 : 55|1@1+ (1,0) [0|1] ""  UNKNOWN
 SG_ P07_FORWARD_SWITCH m7 : 55|1@1+ (1,0) [0|1] ""  UNKNOWN
 SG_ CHECKSUM : 56|4@1+ (1,0) [0|15] ""  UNKNOWN
 SG_ COUNTER : 60|2@1+ (1,0) [0|3] ""  UNKNOWN
 SG_ PROTOCOL_FLAGS : 62|2@1+ (1,0) [0|3] ""  UNKNOWN
VAL_ 1039 P07_FORWARD_SWITCH 0 "OFF" 1 "ON" ;
VAL_ 1039 P05_SCS 0 "OPEN" 1 "SHORT" ;
VAL_ 1039 P07_REVERSE_SWITCH_ATPRVS 0 "OFF" 1 "ON" ;
VAL_ 1039 P05_BRAKE_SWITCH 0 "OFF" 1 "ON" ;
VAL_ 1039 P03_DIRECTION_OF_TURBINE_ROTATION 0 "STOP" 1 "NORMAL_ROTATION" 2 "INVERSE_ROTATION" 3 "NOT_AVAILABLE" ;
VAL_ 1039 P03_DIRECTION_OF_SECONDARY_SHAFT_ROTATION 0 "STOP" 1 "FORWARD" 2 "REVERSE" 3 "NOT_AVAILABLE" ;
VAL_ 1039 P07_PARK_PIN_SWITCH 0 "OFF" 1 "ON" ;
VAL_ 1039 P03_FUEL_CUT_DECEL 0 "OTHER" 1 "FUELCUT" ;
VAL_ 1039 P03_NON_CREEP_CONTROL_STATUS 0 "OTHER" 1 "NON_CREEP" ;
VAL_ 1039 P03_DIRECTION_OF_DRIVE_PULLEY_ROTATION 0 "STOP" 1 "FORWARD" 2 "REVERSE" 3 "NOT_AVAILABLE" ;
VAL_ 1039 P07_A_T_P_SWITCH 0 "OFF" 1 "ON" ;
VAL_ 1039 P07_A_T_R_SWITCH 0 "OFF" 1 "ON" ;
VAL_ 1039 P07_A_T_N_SWITCH 0 "OFF" 1 "ON" ;
VAL_ 1039 P07_A_T_D_SWITCH 0 "OFF" 1 "ON" ;
VAL_ 1039 P07_A_T_S_SWITCH 0 "OFF" 1 "ON" ;
VAL_ 1039 P07_A_T_L_SWITCH 0 "OFF" 1 "ON" ;
VAL_ 1039 P07_SHIFT_LOCK_SOL 0 "OFF" 1 "ON" ;
VAL_ 1039 P07_INHIBITOR_SOL 0 "OFF" 1 "ON" ;
VAL_ 1039 P07_SHIFT_SOL_A 0 "OFF" 1 "ON" ;
VAL_ 1039 P07_SHIFT_SOL_B 0 "OFF" 1 "ON" ;
SG_MUL_VAL_ 1039 UNKNOWN_1 MULTIPLEX_PAGE 0-0;
SG_MUL_VAL_ 1039 UNKNOWN_2 MULTIPLEX_PAGE 1-1;
SG_MUL_VAL_ 1039 P02_ENGINE_SPEED MULTIPLEX_PAGE 2-2;
SG_MUL_VAL_ 1039 P03_OUTPUT_SHAFT_DRIVEN_PULLEY_SPEED_RPM MULTIPLEX_PAGE 3-3;
SG_MUL_VAL_ 1039 P04_INTAKE_AIR_TEMPERATURE MULTIPLEX_PAGE 4-4;
SG_MUL_VAL_ 1039 P05_APP_SENSOR MULTIPLEX_PAGE 5-5;
SG_MUL_VAL_ 1039 P06_DRIVE_PULLEY_SOL_COMMAND MULTIPLEX_PAGE 6-6;
SG_MUL_VAL_ 1039 P07_PRESSURE_CONTROL_SOL_COMMAND MULTIPLEX_PAGE 7-7;
SG_MUL_VAL_ 1039 RSVD_1 MULTIPLEX_PAGE 8-15;
SG_MUL_VAL_ 1039 P00_FRZDTC MULTIPLEX_PAGE 0-0;
SG_MUL_VAL_ 1039 UNKNOWN_3 MULTIPLEX_PAGE 1-1;
SG_MUL_VAL_ 1039 P04_BARO_SENSOR_V MULTIPLEX_PAGE 4-4;
SG_MUL_VAL_ 1039 P05_CVTF_TEMP_SENSOR_V MULTIPLEX_PAGE 5-5;
SG_MUL_VAL_ 1039 P06_DRIVE_PULLEY_SOL_ACTUAL MULTIPLEX_PAGE 6-6;
SG_MUL_VAL_ 1039 P07_PRESSURE_CONTROL_SOL_ACTUAL MULTIPLEX_PAGE 7-7;
SG_MUL_VAL_ 1039 RSVD_2 MULTIPLEX_PAGE 8-15;
SG_MUL_VAL_ 1039 UNKNOWN_4 MULTIPLEX_PAGE 1-1;
SG_MUL_VAL_ 1039 P02_TORQUE_CONVERTER_TURBINE_SPEED MULTIPLEX_PAGE 2-2;
SG_MUL_VAL_ 1039 P03_SECONDARY_SHAFT_SPEED MULTIPLEX_PAGE 3-3;
SG_MUL_VAL_ 1039 P04_MAP_SENSOR_V MULTIPLEX_PAGE 4-4;
SG_MUL_VAL_ 1039 P05_DRIVEN_PULLEY_PRESSURE_SENSOR_V MULTIPLEX_PAGE 5-5;
SG_MUL_VAL_ 1039 P06_DRIVEN_PULLEY_SOL_COMMAND MULTIPLEX_PAGE 6-6;
SG_MUL_VAL_ 1039 RSVD_3 MULTIPLEX_PAGE 7-7;
SG_MUL_VAL_ 1039 RSVD_4 MULTIPLEX_PAGE 8-15;
SG_MUL_VAL_ 1039 P07_SHIFT_SOL_O_P MULTIPLEX_PAGE 7-7;
SG_MUL_VAL_ 1039 P07_SHIFT_SOL_B MULTIPLEX_PAGE 7-7;
SG_MUL_VAL_ 1039 P07_SHIFT_SOL_A MULTIPLEX_PAGE 7-7;
SG_MUL_VAL_ 1039 UNKNOWN_5 MULTIPLEX_PAGE 0-0;
SG_MUL_VAL_ 1039 UNKNOWN_6 MULTIPLEX_PAGE 1-1;
SG_MUL_VAL_ 1039 P03_ABS_WHEEL_SPEED MULTIPLEX_PAGE 3-3;
SG_MUL_VAL_ 1039 P04_TP_SENSOR_1 MULTIPLEX_PAGE 4-4;
SG_MUL_VAL_ 1039 P05_INCLINATION_SENSOR_OUTPUT_VOLTAGE MULTIPLEX_PAGE 5-5;
SG_MUL_VAL_ 1039 P06_DRIVEN_PULLEY_SOL_ACTUAL MULTIPLEX_PAGE 6-6;
SG_MUL_VAL_ 1039 RSVD_5 MULTIPLEX_PAGE 7-7;
SG_MUL_VAL_ 1039 RSVD_6 MULTIPLEX_PAGE 8-15;
SG_MUL_VAL_ 1039 P07_INHIBITOR_SOL MULTIPLEX_PAGE 7-7;
SG_MUL_VAL_ 1039 P07_SHIFT_LOCK_SOL MULTIPLEX_PAGE 7-7;
SG_MUL_VAL_ 1039 UNKNOWN_7 MULTIPLEX_PAGE 0-0;
SG_MUL_VAL_ 1039 UNKNOWN_8 MULTIPLEX_PAGE 1-1;
SG_MUL_VAL_ 1039 P02_INPUT_SHAFT_DRIVE_PULLEY_SPEED_RPM MULTIPLEX_PAGE 2-2;
SG_MUL_VAL_ 1039 P03_VEHICLE_SPEED MULTIPLEX_PAGE 3-3;
SG_MUL_VAL_ 1039 P04_ECT_SENSOR_V MULTIPLEX_PAGE 4-4;
SG_MUL_VAL_ 1039 P05_ELECTRIC_OIL_PUMP_RPM MULTIPLEX_PAGE 5-5;
SG_MUL_VAL_ 1039 P06_LCC_LINEAR_SOL_COMMAND MULTIPLEX_PAGE 6-6;
SG_MUL_VAL_ 1039 RSVD_7 MULTIPLEX_PAGE 7-7;
SG_MUL_VAL_ 1039 RSVD_8 MULTIPLEX_PAGE 8-15;
SG_MUL_VAL_ 1039 P07_A_T_L_SWITCH MULTIPLEX_PAGE 7-7;
SG_MUL_VAL_ 1039 P07_A_T_S_SWITCH MULTIPLEX_PAGE 7-7;
SG_MUL_VAL_ 1039 P07_A_T_D_SWITCH MULTIPLEX_PAGE 7-7;
SG_MUL_VAL_ 1039 P07_A_T_N_SWITCH MULTIPLEX_PAGE 7-7;
SG_MUL_VAL_ 1039 P07_A_T_R_SWITCH MULTIPLEX_PAGE 7-7;
SG_MUL_VAL_ 1039 P07_A_T_P_SWITCH MULTIPLEX_PAGE 7-7;
SG_MUL_VAL_ 1039 UNKNOWN_9 MULTIPLEX_PAGE 1-1;
SG_MUL_VAL_ 1039 P03_DIRECTION_OF_DRIVE_PULLEY_ROTATION MULTIPLEX_PAGE 3-3;
SG_MUL_VAL_ 1039 P04_BATTERY_VOLTAGE MULTIPLEX_PAGE 4-4;
SG_MUL_VAL_ 1039 RSVD_9 MULTIPLEX_PAGE 5-5;
SG_MUL_VAL_ 1039 P06_LCC_LINEAR_SOL_ACTUAL MULTIPLEX_PAGE 6-6;
SG_MUL_VAL_ 1039 RSVD_10 MULTIPLEX_PAGE 7-7;
SG_MUL_VAL_ 1039 RSVD_11 MULTIPLEX_PAGE 8-15;
SG_MUL_VAL_ 1039 P03_NON_CREEP_CONTROL_STATUS MULTIPLEX_PAGE 3-3;
SG_MUL_VAL_ 1039 P03_FUEL_CUT_DECEL MULTIPLEX_PAGE 3-3;
SG_MUL_VAL_ 1039 P07_PARK_PIN_SWITCH MULTIPLEX_PAGE 7-7;
SG_MUL_VAL_ 1039 P03_DIRECTION_OF_SECONDARY_SHAFT_ROTATION MULTIPLEX_PAGE 3-3;
SG_MUL_VAL_ 1039 RSVD_12 MULTIPLEX_PAGE 7-7;
SG_MUL_VAL_ 1039 P03_DIRECTION_OF_TURBINE_ROTATION MULTIPLEX_PAGE 3-3;
SG_MUL_VAL_ 1039 P05_BRAKE_SWITCH MULTIPLEX_PAGE 5-5;
SG_MUL_VAL_ 1039 P07_REVERSE_SWITCH_ATPRVS MULTIPLEX_PAGE 7-7;
SG_MUL_VAL_ 1039 P05_SCS MULTIPLEX_PAGE 5-5;
SG_MUL_VAL_ 1039 P07_FORWARD_SWITCH MULTIPLEX_PAGE 7-7;

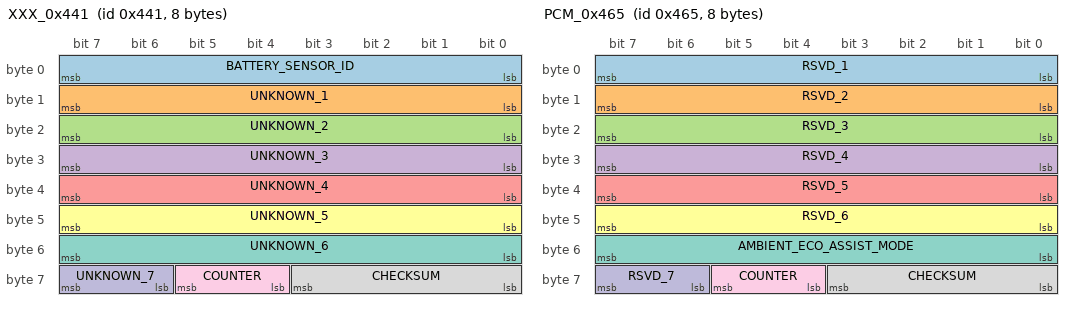
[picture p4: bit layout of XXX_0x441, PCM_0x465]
BO_ 1089 XXX_0x441: 8 PCM
 SG_ BATTERY_SENSOR_ID : 0|8@1+ (1,0) [0|255] ""  UNKNOWN
 SG_ UNKNOWN_1 : 8|8@1+ (1,0) [0|255] ""  UNKNOWN
 SG_ UNKNOWN_2 : 16|8@1+ (1,0) [0|255] ""  UNKNOWN
 SG_ UNKNOWN_3 : 24|8@1+ (1,0) [0|255] ""  UNKNOWN
 SG_ UNKNOWN_4 : 32|8@1+ (1,0) [0|255] ""  UNKNOWN
 SG_ UNKNOWN_5 : 40|8@1+ (1,0) [0|255] ""  UNKNOWN
 SG_ UNKNOWN_6 : 48|8@1+ (1,0) [0|255] ""  UNKNOWN
 SG_ CHECKSUM : 56|4@1+ (1,0) [0|15] ""  UNKNOWN
 SG_ COUNTER : 60|2@1+ (1,0) [0|3] ""  UNKNOWN
 SG_ UNKNOWN_7 : 62|2@1+ (1,0) [0|3] ""  UNKNOWN

BO_ 1108 XXX_0x454: 8 PCM
 SG_ RETAINED_MODEL_QUANTITY_RAW : 0|8@1+ (1,0) [0|255] ""  UNKNOWN
 SG_ BARO_SENSOR : 8|8@1+ (1,0) [0|255] ""  UNKNOWN
 SG_ UNKNOWN_1 : 16|4@1+ (1,0) [0|15] ""  UNKNOWN
 SG_ BAROMETRIC_SENSOR_FAULT_AGGREGATE : 20|1@1+ (1,0) [0|1] ""  UNKNOWN
 SG_ SIGNED_STATE_BIT5_RAW : 21|1@1+ (1,0) [0|1] ""  UNKNOWN
 SG_ MODEL_HOLD_ACTIVE_RAW : 22|1@1+ (1,0) [0|1] ""  UNKNOWN
 SG_ STATUS_BIT_1 : 23|1@1+ (1,0) [0|1] ""  UNKNOWN
 SG_ SCALED_MODEL_QUANTITY_RAW : 31|16@0+ (1,0) [0|65535] ""  UNKNOWN
 SG_ RSVD_1 : 40|8@1+ (1,0) [0|255] ""  UNKNOWN
 SG_ ELECTRICAL_MONITOR_SECONDARY_RAW : 48|1@1+ (1,0) [0|1] ""  UNKNOWN
 SG_ STATUS_BIT_2 : 49|1@1+ (1,0) [0|1] ""  UNKNOWN
 SG_ STATUS_BIT_3 : 50|1@1+ (1,0) [0|1] ""  UNKNOWN
 SG_ ELECTRICAL_MONITOR_PRIMARY_RAW : 51|1@1+ (1,0) [0|1] ""  UNKNOWN
 SG_ RSVD_2 : 52|1@1+ (1,0) [0|1] ""  UNKNOWN
 SG_ POST_CRANK_CONTROL_LATCH_RAW : 53|1@1+ (1,0) [0|1] ""  UNKNOWN
 SG_ VARIANT_CODE_MATCH_RAW : 54|1@1+ (1,0) [0|1] ""  UNKNOWN
 SG_ MONITOR_HOLD_RAW : 55|1@1+ (1,0) [0|1] ""  UNKNOWN
 SG_ CHECKSUM : 56|4@1+ (1,0) [0|15] ""  UNKNOWN
 SG_ COUNTER : 60|2@1+ (1,0) [0|3] ""  UNKNOWN
 SG_ RSVD_3 : 62|2@1+ (1,0) [0|3] ""  UNKNOWN

BO_ 1125 PCM_0x465: 8 PCM
 SG_ RSVD_1 : 0|8@1+ (1,0) [0|255] ""  UNKNOWN
 SG_ RSVD_2 : 8|8@1+ (1,0) [0|255] ""  UNKNOWN
 SG_ RSVD_3 : 16|8@1+ (1,0) [0|255] ""  UNKNOWN
 SG_ RSVD_4 : 24|8@1+ (1,0) [0|255] ""  UNKNOWN
 SG_ RSVD_5 : 32|8@1+ (1,0) [0|255] ""  UNKNOWN
 SG_ RSVD_6 : 40|8@1+ (1,0) [0|255] ""  UNKNOWN
 SG_ AMBIENT_ECO_ASSIST_MODE : 48|8@1+ (1,0) [0|255] ""  UNKNOWN
 SG_ CHECKSUM : 56|4@1+ (1,0) [0|15] ""  UNKNOWN
 SG_ COUNTER : 60|2@1+ (1,0) [0|3] ""  UNKNOWN
 SG_ RSVD_7 : 62|2@1+ (1,0) [0|3] ""  UNKNOWN
VAL_ 1125 AMBIENT_ECO_ASSIST_MODE 1 "WHITE" 2 "LIGHT_GREEN" 3 "GREEN" ;
